# DP32G030 register map
File version: 1.0
CPU: CM0 r0p0, little endian, no MPU, no FPU, 4 interrupt priority bits
Registers are 32-bit, read-write, reset 0x0 unless marked. A register's access mark holds for its fields unless they carry their own. Offsets are from the block's base; [hi:lo] are bit positions; {n}, {i} and the like mark numbered series.

## SYSCON — System Configuration unit
Base 0x40000000
0x00 CLK_SEL access per field reset 0x2 — Clock Select Register
  [11] PLL_CLK_SEL ro — PLL Input Clock Selection 0: RCHF 1: XTAH
  [11:10] SARADC_SMPL_CLK_SEL wo — SARADC Sampling Clock Selection 00: 1 division of the system clock 01: 2 divisions of the system clock 10: 4 divisions of the system clock 11: 8-division frequency of the system clock
  [10:9] SARADC_SMPL_CLK_SEL ro — SARADC Sampling Clock Selection 00: 1 division of the system clock 01: 2 divisions of the system clock 10: 4 divisions of the system clock 11: 8-division frequency of the system clock
  [7] PLL_CLK_SEL wo — PLL Input Clock Selection 0: RCHF 1: XTAH
  [6:4] SRC_CLK_SEL rw — Source clock (SRC_CLK) selection 000: RCHF 001: RCLF 010: XTAH 011: XTAL 100: PLL
  [3:1] DIV_CLK_SEL rw — Divided frequency clock (DIV_CLK) selection 000: 1-division frequency of SRC_CLK 001: 2 divisions of SRC_CLK 010: 4-division frequency of SRC_CLK 011: 8-division frequency of SRC_CLK 100: 16 divisions of SRC_CLK 101: 32 divisions of SRC_CLK
  [0] SYS_CLK_SEL rw — System Clock Selection 0: RCHF clock 1: DIV_CLK Clock
0x04 DIV_CLK_GATE reset 0x1 — Divided Clock Gating Register
  [0] DIV_CLK_GATE — Fractional Clock Gating 1: Divided Clock Output 0: Frequency division clock disabled Note: When it is necessary to change the DIV_CLK_SEL or SRC_CLK_SEL register, it is necessary to switch the system clock to RCHF first, then set this register to 0 to turn off DIV_CLK, and then finally change the value of DIV_CLK_SEL or SRC_CLK_SEL, so as to ensure the reliability of the clock.
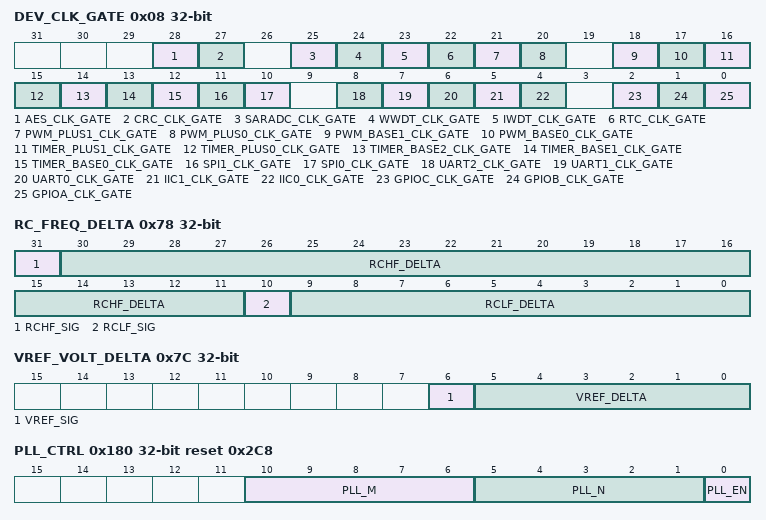
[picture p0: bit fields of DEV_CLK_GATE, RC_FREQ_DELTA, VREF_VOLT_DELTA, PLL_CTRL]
0x08 DEV_CLK_GATE — Peripheral Clock Gating Registers
  [28] AES_CLK_GATE — AES128 Module Clock Gating
  [27] CRC_CLK_GATE — CRC Module Clock Gating
  [25] SARADC_CLK_GATE — SARADC_CTRL Module Clock Gating
  [24] WWDT_CLK_GATE — WWDT Module Clock Gating
  [23] IWDT_CLK_GATE — IWDT Module Clock Gating
  [22] RTC_CLK_GATE — RTC Module Clock Gating
  [21] PWM_PLUS1_CLK_GATE — PWM_PLUS1 Module Clock Gating
  [20] PWM_PLUS0_CLK_GATE — PWM_PLUS0 Module Clock Gating
  [18] PWM_BASE1_CLK_GATE — PWM_BASE1 Module Clock Gating
  [17] PWM_BASE0_CLK_GATE — PWM_BASE0 Module Clock Gating
  [16] TIMER_PLUS1_CLK_GATE — TIMER_PLUS1 Module Clock Gating
  [15] TIMER_PLUS0_CLK_GATE — TIMER_PLUS0 Module Clock Gating
  [14] TIMER_BASE2_CLK_GATE — TIMER_BASE2 Module Clock Gating
  [13] TIMER_BASE1_CLK_GATE — TIMER_BASE1 Module Clock Gating
  [12] TIMER_BASE0_CLK_GATE — TIMER_BASE0 Module Clock Gating
  [11] SPI1_CLK_GATE — SPI1 Module Clock Gating
  [10] SPI0_CLK_GATE — SPI0 Module Clock Gating
  [8] UART2_CLK_GATE — UART2 Module Clock Gating
  [7] UART1_CLK_GATE — UART1 Module Clock Gating
  [6] UART0_CLK_GATE — UART0 Module Clock Gating
  [5] IIC1_CLK_GATE — IIC1 Module Clock Gating
  [4] IIC0_CLK_GATE — IIC0 Module Clock Gating
  [2] GPIOC_CLK_GATE — GPIOC Module Clock Gating
  [1] GPIOB_CLK_GATE — GPIOB Module Clock Gating
  [0] GPIOA_CLK_GATE — GPIOA Module Clock Gating
0x78 RC_FREQ_DELTA — RCHF/RCLF True Frequency Value Difference Register
  [31] RCHF_SIG — 1: Indicates that RCHF_DELTA is positive. 0: Indicates that RCHF_DELTA is negative.
  [30:11] RCHF_DELTA — RCHF Difference between actual test frequency and 48MHz Note: The true frequency is the sum of 48MHz and the difference.
  [10] RCLF_SIG — 1: Indicates that RCLF_DELTA is positive. 0: Indicates that RCLF_DELTA is negative.
  [9:0] RCLF_DELTA — RCLF Difference between actual test frequency and 32.768KHz Note: The true frequency is the sum of 32.768KHz and the difference.
0x7C VREF_VOLT_DELTA — VREFTrue Voltage Difference Register
  [6] VREF_SIG — 1: Indicates that VREF_DELTA is positive. 0: Indicates that VREF_DELTA is negative.
  [5:0] VREF_DELTA — VREF Difference between actual test reference voltage value and theoretical value (in mv) Note: The true voltage value is the sum of the theoretical value and the difference.
{0x80+4i} CHIP_ID{i} access not given (i=0..3) — Equipment ID register {i}
0x180 PLL_CTRL reset 0x2C8 — PLL control register
  [10:6] PLL_M — PLL Reference Clock Divider 00000:1 crossover frequency 00001: 2 crossover frequency 00010: 3 crossover frequency 00011: 4 crossover frequency ...... 11110:31 Crossover frequency 11111: 32 crossover frequency
  [5:1] PLL_N — PLL Feedback Clock Division 00000: 2 crossover frequency 00001: 4 crossover frequency 00010: 6 crossover frequency 00011: 8 crossover frequency ...... 11110: 62 crossover frequency 11111: 64 crossover frequency
  [0] PLL_EN — PLL enable control bit 0: Turn off PLL 1: Enable PLL Note: The PLL will not lock until at least 30us after it is turned on.
0x184 PLL_ST ro — PLL status register
  [0] PLL_LOCK — PLL Lock Status Bit 0: not locked 1: Locked, PLL clock can be used
